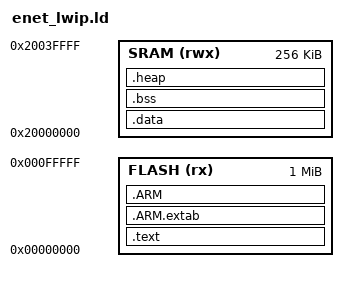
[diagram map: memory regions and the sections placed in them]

HEAP_SIZE = 1024;

MEMORY
{
    FLASH (rx) : ORIGIN = 0x00000000, LENGTH = 0x00100000
    SRAM (rwx) : ORIGIN = 0x20000000, LENGTH = 0x00040000
}

SECTIONS
{
    .text :
    {
        _text = .;
        KEEP(*(.isr_vector))
        *(.text*)
        *(.rodata*)
        KEEP (*(.init))
        KEEP (*(.fini))
        _etext = .;
    } > FLASH

    .ARM.extab :
    {
        *(.ARM.extab* .gnu.linkonce.armextab.*)
    } > FLASH

    .ARM :
    {
        __exidx_start = .;
        *(.ARM.exidx*)
        __exidx_end = .;
    } > FLASH

    __end_code = .;

    .data : AT(__end_code)
    {
        _data = .;
        _ldata = LOADADDR (.data);
        *(vtable)
        *(.data*)
        _edata = .;
    } > SRAM

    .bss :
    {
        _bss = .;
        __bss_start__ = .;
        *(.bss*)
        *(COMMON)
        _ebss = .;
        __bss_end__ = .;
    } > SRAM

    .heap : AT(_ebss)
    {
        . = ALIGN(8);
        __end__ = .;
        PROVIDE(end = .);
        __HeapBase = .;
        . += HEAP_SIZE;
        __HeapLimit = .;
    } > SRAM
}
